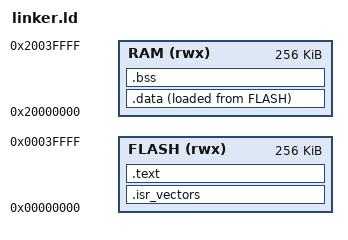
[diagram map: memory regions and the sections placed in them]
/* linker.ld
 *
 * Copyright (C) 2026 wolfSSL Inc.
 *
 * This file is part of wolfHAL.
 *
 * wolfHAL is free software; you can redistribute it and/or modify
 * it under the terms of the GNU General Public License as published by
 * the Free Software Foundation; either version 3 of the License, or
 * (at your option) any later version.
 *
 * wolfHAL is distributed in the hope that it will be useful,
 * but WITHOUT ANY WARRANTY; without even the implied warranty of
 * MERCHANTABILITY or FITNESS FOR A PARTICULAR PURPOSE.  See the
 * GNU General Public License for more details.
 *
 * You should have received a copy of the GNU General Public License
 * along with this program; if not, write to the Free Software
 * Foundation, Inc., 51 Franklin Street, Fifth Floor, Boston, MA 02110-1335, USA
 */

/* TODO: set the real flash/RAM sizes from the datasheet. */
MEMORY
{
    FLASH (rwx) : ORIGIN = 0x00000000, LENGTH = 256K
    RAM (rwx)  : ORIGIN = 0x20000000, LENGTH = 256K
}

ENTRY(Reset_Handler)

SECTIONS
{
    .isr_vectors :
    {
        . = ALIGN(4);
        KEEP(*(.isr_vectors))
        . = ALIGN(4);
    } > FLASH

    .text :
    {
        . = ALIGN(4);
        *(.text*)
        *(.rodata*)
        . = ALIGN(4);
    } > FLASH

    .data :
    {
        . = ALIGN(4);
        _sdata = .;
        *(.data*)
        . = ALIGN(4);
        _edata = .;
    } > RAM AT > FLASH

    _sidata = LOADADDR(.data);

    .bss :
    {
        . = ALIGN(4);
        _sbss = .;
        *(.bss*)
        *(COMMON)
        . = ALIGN(4);
        _ebss = .;
    } > RAM

    /* Set stack top to end of RAM */
    _estack = ORIGIN(RAM) + LENGTH(RAM);

    /DISCARD/ :
    {
        *(.comment)
        *(.ARM.attributes)
    }
}
